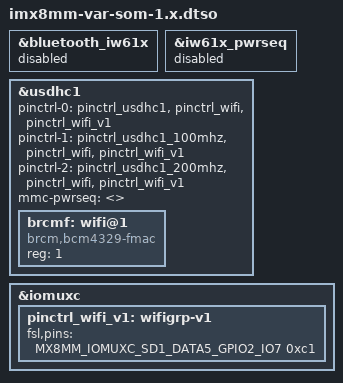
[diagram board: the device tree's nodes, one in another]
// SPDX-License-Identifier: (GPL-2.0+ OR MIT)
/*
 * Device tree overlay for VAR-SOM-MX8M-MINI 1.x modules.
 *
 * Copyright 2025-2026 Variscite Ltd.
 */

/dts-v1/;
/plugin/;

#include "imx8mm-pinfunc.h"

&bluetooth_iw61x {
	status = "disabled";
};

&iw61x_pwrseq {
	status = "disabled";
};

&usdhc1 {
	#address-cells = <1>;
	#size-cells = <0>;
	pinctrl-0 = <&pinctrl_usdhc1>, <&pinctrl_wifi>, <&pinctrl_wifi_v1>;
	pinctrl-1 = <&pinctrl_usdhc1_100mhz>, <&pinctrl_wifi>, <&pinctrl_wifi_v1>;
	pinctrl-2 = <&pinctrl_usdhc1_200mhz>, <&pinctrl_wifi>, <&pinctrl_wifi_v1>;
	mmc-pwrseq = <>;

	brcmf: wifi@1 {
		reg = <1>;
		compatible = "brcm,bcm4329-fmac";
	};
};

&iomuxc {
	pinctrl_wifi_v1: wifigrp-v1 {
		fsl,pins = <
			MX8MM_IOMUXC_SD1_DATA5_GPIO2_IO7		0xc1
		>;
	};
};
